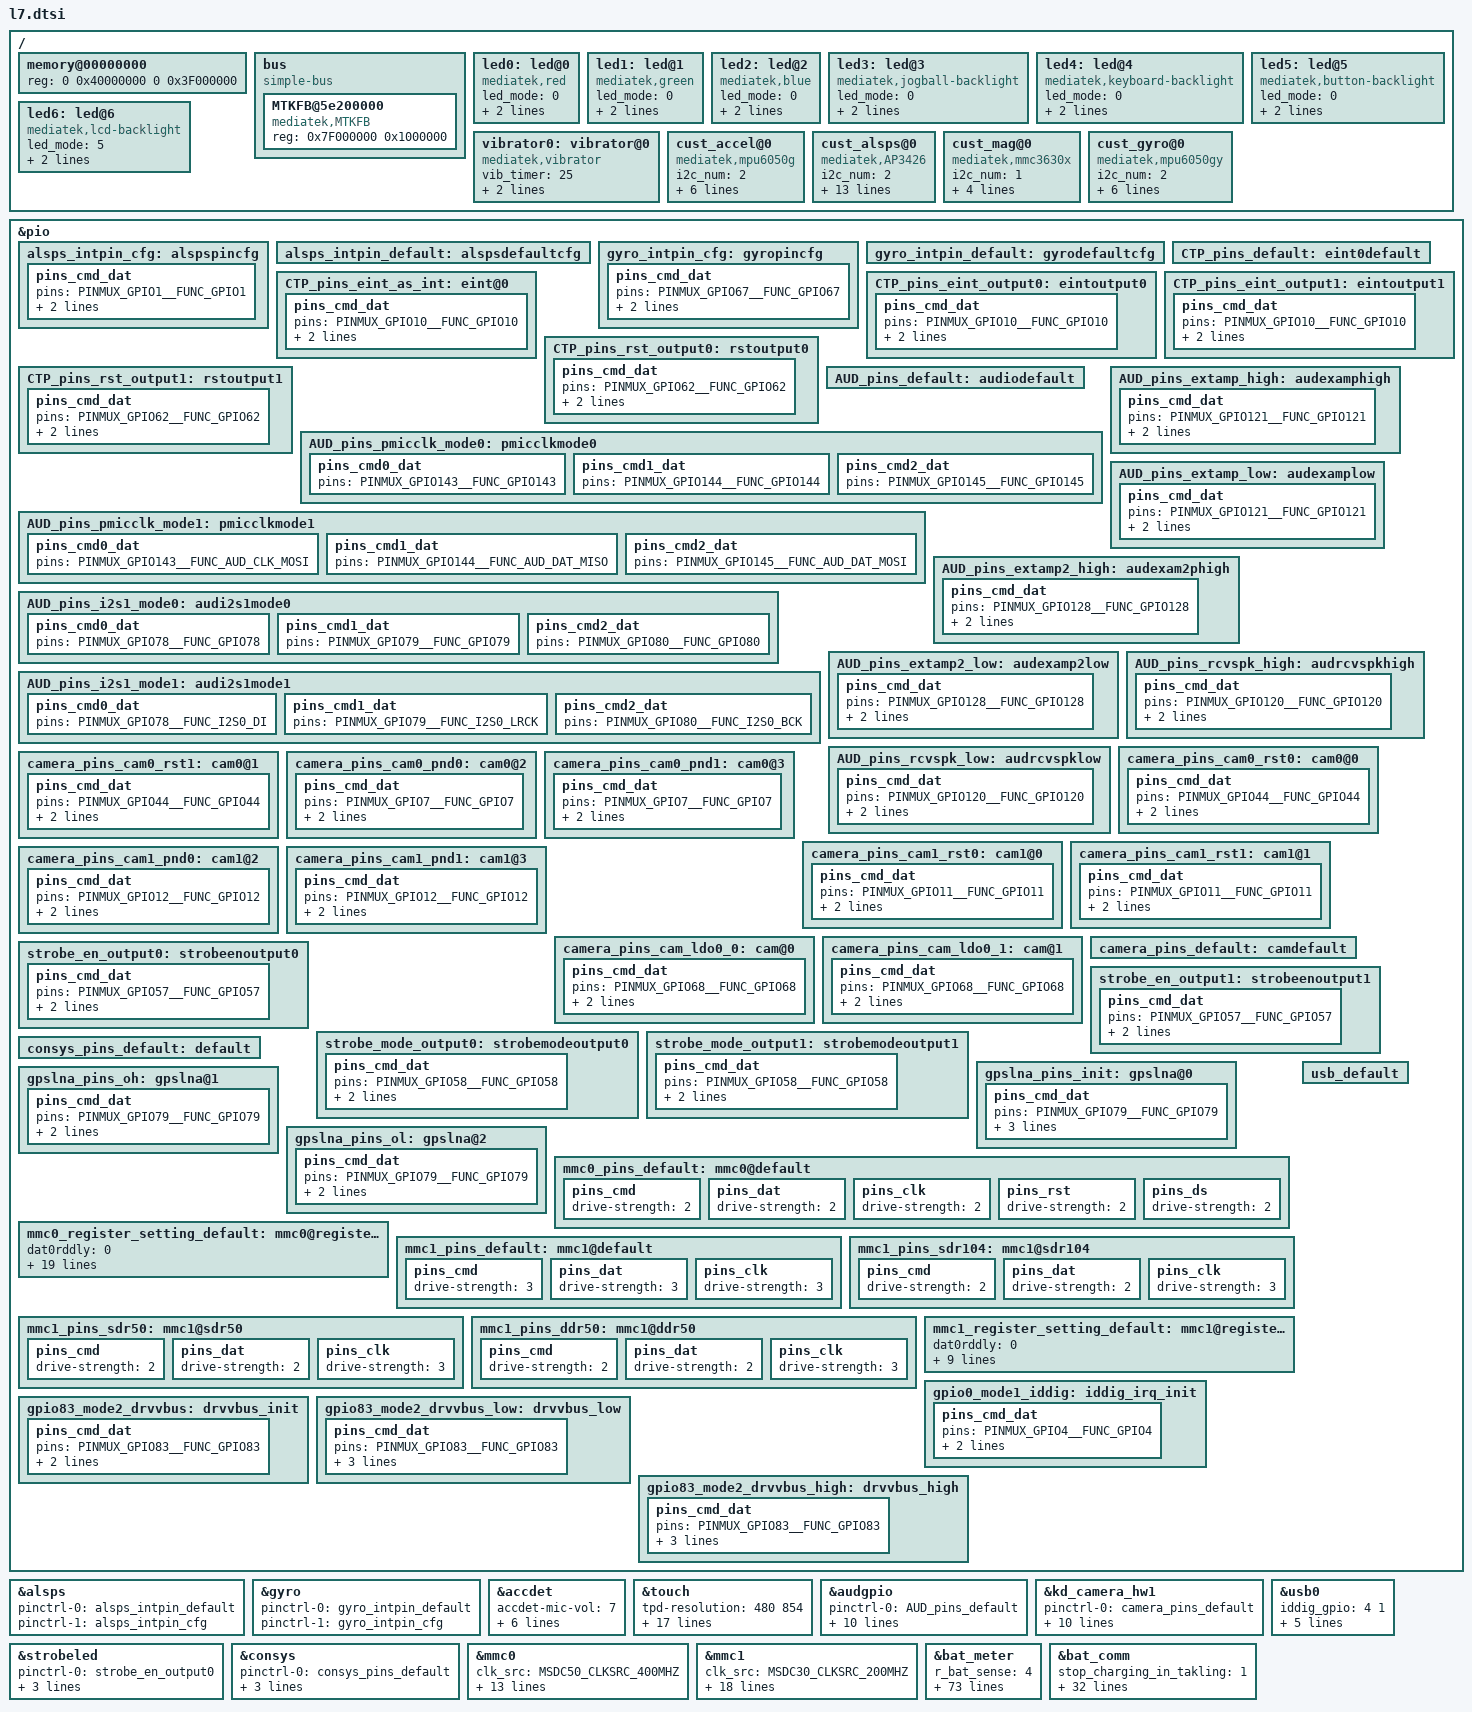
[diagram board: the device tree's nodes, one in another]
#include "mt6735m.dtsi"

/ {
memory@00000000 {
		device_type = "memory";
		reg = <0 0x40000000 0 0x3F000000>;
	};

	bus {
		compatible = "simple-bus";
		#address-cells = <1>;
		#size-cells = <1>;
		ranges = <0 0 0 0xffffffff>;

		MTKFB@5e200000 {
			compatible = "mediatek,MTKFB";
			reg = <0x7F000000 0x1000000>;
		};

	};
	led0:led@0 {
		compatible = "mediatek,red";
		led_mode = <0>;
		data = <1>;
		pwm_config = <0 0 0 0 0>;
	};
	led1:led@1 {
		compatible = "mediatek,green";
		led_mode = <0>;
		data = <1>;
		pwm_config = <0 0 0 0 0>;
	};
	led2:led@2 {
		compatible = "mediatek,blue";
		led_mode = <0>;
		data = <1>;
		pwm_config = <0 0 0 0 0>;
	};
	led3:led@3 {
		compatible = "mediatek,jogball-backlight";
		led_mode = <0>;
		data = <1>;
		pwm_config = <0 0 0 0 0>;
	};
	led4:led@4 {
		compatible = "mediatek,keyboard-backlight";
		led_mode = <0>;
		data = <1>;
		pwm_config = <0 0 0 0 0>;
	};
	led5:led@5 {
		compatible = "mediatek,button-backlight";
		led_mode = <0>;
		data = <1>;
		pwm_config = <0 0 0 0 0>;
	};
	led6:led@6 {
		compatible = "mediatek,lcd-backlight";
		led_mode = <5>;
		data = <1>;
		pwm_config = <0 0 0 0 0>;
	};
	vibrator0:vibrator@0 {
		compatible = "mediatek,vibrator";
		vib_timer = <25>;
		vib_limit = <9>;
		vib_vol= <5>;
	};
 /* sensor standardization */
		cust_accel@0 {
		compatible				= "mediatek,mpu6050g";
		i2c_num				= <2>;
		i2c_addr				= <0x68 0 0 0>;
		direction				= <7>;
		power_id				= <0xffff>;
		power_vol				= <0>;
		firlen					= <0>;
		is_batch_supported			= <0>;
		};

		cust_alsps@0 {
		compatible				= "mediatek,AP3426";
		i2c_num				= <2>;
		i2c_addr				= <0x1E 0 0 0>;
		polling_mode_ps			= <0>;
		polling_mode_als		= <1>;
		power_id				= <0xffff>;
		power_vol				= <0>;
		als_level = <0 1 1 7 15 15 100 1000 2000 3000 6000 10000 14000 18000 20000>;
		als_value = <40 40 90 90 160 160 225 320 640 1280 1280 2600 2600 2600 10240 10240>;
		ps_threshold_high		=  <300>;
		ps_threshold_low		=  <100>;
		is_batch_supported_ps	= <0>;
		is_batch_supported_als	= <0>;
		};

		cust_mag@0 {
		compatible			= "mediatek,mmc3630x";
		i2c_num				= <1>;
		i2c_addr			= <0x30 0 0 0>;
		direction			= <7>;
		power_id			= <0xffff>;
		power_vol			= <0>;
		/* is_batch_supported		= <0>; */
		};

		cust_gyro@0 {
		compatible				= "mediatek,mpu6050gy";
		i2c_num				= <2>;
		i2c_addr				= <0x69 0 0 0>;
		direction				= <7>;
		power_id				= <0xffff>;
		power_vol				= <0>;
		firlen					= <0>;
		is_batch_supported	= <0>;
		};
};
/* sensor gpio standization */
&pio {
	alsps_intpin_cfg: alspspincfg {

	    pins_cmd_dat {
			pins = <PINMUX_GPIO1__FUNC_GPIO1>;
			slew-rate = <0>;
			bias-pull-up = <00>;
		};
	};

	alsps_intpin_default: alspsdefaultcfg {

	};

	gyro_intpin_cfg: gyropincfg {

	    pins_cmd_dat {
			pins = <PINMUX_GPIO67__FUNC_GPIO67>;
			slew-rate = <0>;
			bias-pull-down = <00>;
		};
	};

	gyro_intpin_default: gyrodefaultcfg {

	};
};
&alsps {
	pinctrl-names = "pin_default", "pin_cfg";
	pinctrl-0 = <&alsps_intpin_default>;
	pinctrl-1 = <&alsps_intpin_cfg>;
	status = "okay";

};

&gyro {
	pinctrl-names = "pin_default", "pin_cfg";
	pinctrl-0 = <&gyro_intpin_default>;
	pinctrl-1 = <&gyro_intpin_cfg>;
	status = "okay";

};
/* sensor end */

&accdet {
		accdet-mic-vol = <7>;
		headset-mode-setting = <0x500 0x200 1 0x1F0 0x800 0x800 0x20>;
		accdet-plugout-debounce = <20>;
		/*1:ACC mode, 2:low cost without in bias, 6:low cost with in bias*/
		accdet-mic-mode = <2>;
		/*0--MD_MAX--UP_MAX--DW_MAX*/
		headset-three-key-threshold = <0 60 180 500>;
		/*0--MD_MAX--VOICE_MAX--UP_MAX--DW_MAX*/
		headset-four-key-threshold = <0 58 121 192 450>;
};
&touch {
	tpd-resolution = <480 854>;
	use-tpd-button = <0>;
	tpd-key-num = <3>;
	tpd-key-local= <139 172 158 0>;
	tpd-key-dim-local = <90 883 100 40 230 883 100 40 370 883 100 40 0 0 0 0>;
	tpd-max-touch-num = <5>;
	tpd-filter-enable = <1>;
	tpd-filter-pixel-density = <93>;
	tpd-filter-custom-prameters = <0 0 0 0 0 0 0 0 0 0 0 0>;
	tpd-filter-custom-speed = <0 0 0>;
	pinctrl-names = "default", "state_eint_as_int", "state_eint_output0", "state_eint_output1",
		"state_rst_output0", "state_rst_output1";
	pinctrl-0 = <&CTP_pins_default>;
	pinctrl-1 = <&CTP_pins_eint_as_int>;
	pinctrl-2 = <&CTP_pins_eint_output0>;
	pinctrl-3 = <&CTP_pins_eint_output1>;
	pinctrl-4 = <&CTP_pins_rst_output0>;
	pinctrl-5 = <&CTP_pins_rst_output1>;
	status = "okay";
};
&pio {
	CTP_pins_default: eint0default {
	};
	CTP_pins_eint_as_int: eint@0 {
		pins_cmd_dat {
			pins = <PINMUX_GPIO10__FUNC_GPIO10>;
			slew-rate = <0>;
			bias-disable;
		};
	};
	CTP_pins_eint_output0: eintoutput0 {
		pins_cmd_dat {
			pins = <PINMUX_GPIO10__FUNC_GPIO10>;
			slew-rate = <1>;
			output-low;
		};
	};
	CTP_pins_eint_output1: eintoutput1 {
		pins_cmd_dat {
			pins = <PINMUX_GPIO10__FUNC_GPIO10>;
			slew-rate = <1>;
			output-high;
		};
	};
	CTP_pins_rst_output0: rstoutput0 {
		pins_cmd_dat {
			pins = <PINMUX_GPIO62__FUNC_GPIO62>;
			slew-rate = <1>;
			output-low;
		};
	};
	CTP_pins_rst_output1: rstoutput1 {
		pins_cmd_dat {
			pins = <PINMUX_GPIO62__FUNC_GPIO62>;
			slew-rate = <1>;
			output-high;
		};
	};
};
/* TOUCH end */
/* AUDIO GPIO standardization */
&audgpio {
	pinctrl-names = "default", "audpmicclk-mode0", "audpmicclk-mode1", "audi2s1-mode0", "audi2s1-mode1", "extamp-pullhigh", "extamp-pulllow", "extamp2-pullhigh", "extamp2-pulllow", "rcvspk-pullhigh", "rcvspk-pulllow";
	pinctrl-0 = <&AUD_pins_default>;
	pinctrl-1 = <&AUD_pins_pmicclk_mode0>;
	pinctrl-2 = <&AUD_pins_pmicclk_mode1>;
	pinctrl-3 = <&AUD_pins_i2s1_mode0>;
	pinctrl-4 = <&AUD_pins_i2s1_mode1>;
	pinctrl-5 = <&AUD_pins_extamp_high>;
	pinctrl-6 = <&AUD_pins_extamp_low>;
	pinctrl-7 = <&AUD_pins_extamp2_high>;
	pinctrl-8 = <&AUD_pins_extamp2_low>;
	pinctrl-9 = <&AUD_pins_rcvspk_high>;
	pinctrl-10 = <&AUD_pins_rcvspk_low>;
	status = "okay";
};
&pio {
	AUD_pins_default: audiodefault {
	};
	AUD_pins_pmicclk_mode0: pmicclkmode0 {
		pins_cmd0_dat {
			pins = <PINMUX_GPIO143__FUNC_GPIO143>;
		};
		pins_cmd1_dat {
			pins = <PINMUX_GPIO144__FUNC_GPIO144>;
		};
		pins_cmd2_dat {
			pins = <PINMUX_GPIO145__FUNC_GPIO145>;
		};
	};
	AUD_pins_pmicclk_mode1: pmicclkmode1 {
		pins_cmd0_dat {
			pins = <PINMUX_GPIO143__FUNC_AUD_CLK_MOSI>;
		};
		pins_cmd1_dat {
			pins = <PINMUX_GPIO144__FUNC_AUD_DAT_MISO>;
		};
		pins_cmd2_dat {
			pins = <PINMUX_GPIO145__FUNC_AUD_DAT_MOSI>;
		};
	};
	AUD_pins_i2s1_mode0: audi2s1mode0 {
		pins_cmd0_dat {
			pins = <PINMUX_GPIO78__FUNC_GPIO78>;
		};
		pins_cmd1_dat {
			pins = <PINMUX_GPIO79__FUNC_GPIO79>;
		};
		pins_cmd2_dat {
			pins = <PINMUX_GPIO80__FUNC_GPIO80>;
		};
	};
	AUD_pins_i2s1_mode1: audi2s1mode1 {
		pins_cmd0_dat {
			pins = <PINMUX_GPIO78__FUNC_I2S0_DI>;
		};
		pins_cmd1_dat {
			pins = <PINMUX_GPIO79__FUNC_I2S0_LRCK>;
		};
		pins_cmd2_dat {
			pins = <PINMUX_GPIO80__FUNC_I2S0_BCK>;
		};
	};
	AUD_pins_extamp_high: audexamphigh {
		pins_cmd_dat {
			pins = <PINMUX_GPIO121__FUNC_GPIO121>;
				slew-rate = <1>;
				output-high;
		};
	};
	AUD_pins_extamp_low: audexamplow {
		pins_cmd_dat {
			pins = <PINMUX_GPIO121__FUNC_GPIO121>;
				slew-rate = <1>;
				output-low;
		};
	};
	AUD_pins_extamp2_high: audexam2phigh {
		pins_cmd_dat {
			pins = <PINMUX_GPIO128__FUNC_GPIO128>;
				slew-rate = <1>;
				output-high;
		};
	};
	AUD_pins_extamp2_low: audexamp2low {
		pins_cmd_dat {
			pins = <PINMUX_GPIO128__FUNC_GPIO128>;
				slew-rate = <1>;
				output-low;
		};
	};
	AUD_pins_rcvspk_high: audrcvspkhigh {
		pins_cmd_dat {
			pins = <PINMUX_GPIO120__FUNC_GPIO120>;
				slew-rate = <1>;
				output-high;
		};
	};
	AUD_pins_rcvspk_low: audrcvspklow {
		pins_cmd_dat {
			pins = <PINMUX_GPIO120__FUNC_GPIO120>;
				slew-rate = <1>;
				output-low;
		};
	};
};
/* AUDIO end */
/* CAMERA GPIO standardization */
&pio {
	camera_pins_cam0_rst0: cam0@0 {
	    pins_cmd_dat {
			pins = <PINMUX_GPIO44__FUNC_GPIO44>;/*GPIO_CAMERA_CMRST_PIN*/
			slew-rate = <1>; /*direction 0:in, 1:out*/
			output-low;/*direction out used only. output_low or high*/
		};
	};
	camera_pins_cam0_rst1: cam0@1 {
	    pins_cmd_dat {
			pins = <PINMUX_GPIO44__FUNC_GPIO44>;/*GPIO_CAMERA_CMRST_PIN*/
			slew-rate = <1>;
			output-high;
		};
	};
	camera_pins_cam0_pnd0: cam0@2 {
	    pins_cmd_dat {
			pins = <PINMUX_GPIO7__FUNC_GPIO7>;/*GPIO_CAMERA_CMPDN_PIN*/
			slew-rate = <1>;
			output-low;
		};
	};
	camera_pins_cam0_pnd1: cam0@3 {
	    pins_cmd_dat {
			pins = <PINMUX_GPIO7__FUNC_GPIO7>;/*GPIO_CAMERA_CMPDN_PIN*/
			slew-rate = <1>;
			output-high;
		};
	};
	camera_pins_cam1_rst0: cam1@0 {
	    pins_cmd_dat {
			pins = <PINMUX_GPIO11__FUNC_GPIO11>;/*GPIO_CAMERA_CMRST1_PIN*/
			slew-rate = <1>; /*direction 0:in, 1:out*/
			output-low;/*direction out used only. output_low or high*/
		};
	};
	camera_pins_cam1_rst1: cam1@1 {
	    pins_cmd_dat {
			pins = <PINMUX_GPIO11__FUNC_GPIO11>;/*GPIO_CAMERA_CMRST1_PIN*/
			slew-rate = <1>;
			output-high;
		};
	};
	camera_pins_cam1_pnd0: cam1@2 {
	    pins_cmd_dat {
			pins = <PINMUX_GPIO12__FUNC_GPIO12>;/*GPIO_CAMERA_CMPDN1_PIN*/
			slew-rate = <1>;
			output-low;
		};
	};
	camera_pins_cam1_pnd1: cam1@3 {
	    pins_cmd_dat {
			pins = <PINMUX_GPIO12__FUNC_GPIO12>;/*GPIO_CAMERA_CMPDN1_PIN*/
			slew-rate = <1>;
			output-high;
		};
	};
	camera_pins_cam_ldo0_0: cam@0 {
	    pins_cmd_dat {
			pins = <PINMUX_GPIO68__FUNC_GPIO68>;/*GPIO_SPI_MOSI_PIN*/
			slew-rate = <1>;
			output-low;
		};
	};
	camera_pins_cam_ldo0_1: cam@1 {
		pins_cmd_dat {
			pins = <PINMUX_GPIO68__FUNC_GPIO68>;/*GPIO_SPI_MOSI_PIN*/
			slew-rate = <1>;
			output-high;
		};
	};
	camera_pins_default: camdefault {
	};

};

&kd_camera_hw1 {
	pinctrl-names = "default", "cam0_rst0", "cam0_rst1", "cam0_pnd0", "cam0_pnd1",
			"cam1_rst0", "cam1_rst1", "cam1_pnd0", "cam1_pnd1","cam_ldo0_0", "cam_ldo0_1";
	pinctrl-0 = <&camera_pins_default>;
	pinctrl-1 = <&camera_pins_cam0_rst0>;
	pinctrl-2 = <&camera_pins_cam0_rst1>;
	pinctrl-3 = <&camera_pins_cam0_pnd0>;
	pinctrl-4 = <&camera_pins_cam0_pnd1>;
	pinctrl-5 = <&camera_pins_cam1_rst0>;
	pinctrl-6 = <&camera_pins_cam1_rst1>;
	pinctrl-7 = <&camera_pins_cam1_pnd0>;
	pinctrl-8 = <&camera_pins_cam1_pnd1>;
	pinctrl-9 = <&camera_pins_cam_ldo0_0>;
	pinctrl-10 = <&camera_pins_cam_ldo0_1>;
	status = "okay";

};
/* CAMERA GPIO end */

/* strobe standardization */
&strobeled {
	pinctrl-names = "state_strobe_en_output0", "state_strobe_en_output1", "state_strobe_mode_output0", "state_strobe_mode_output1";
	pinctrl-0 = <&strobe_en_output0>;
	pinctrl-1 = <&strobe_en_output1>;
	pinctrl-2 = <&strobe_mode_output0>;
	pinctrl-3 = <&strobe_mode_output1>;
	status = "okay";
};
&pio {
	strobe_en_output0: strobeenoutput0 {
		pins_cmd_dat {
			pins = <PINMUX_GPIO57__FUNC_GPIO57>;
			slew-rate = <1>;
			output-low;
		};
	};
	strobe_en_output1: strobeenoutput1 {
		pins_cmd_dat {
			pins = <PINMUX_GPIO57__FUNC_GPIO57>;
			slew-rate = <1>;
			output-high;
		};
	};
	strobe_mode_output0: strobemodeoutput0 {
		pins_cmd_dat {
			pins = <PINMUX_GPIO58__FUNC_GPIO58>;
			slew-rate = <1>;
			output-low;
		};
	};
	strobe_mode_output1: strobemodeoutput1 {
		pins_cmd_dat {
			pins = <PINMUX_GPIO58__FUNC_GPIO58>;
			slew-rate = <1>;
			output-high;
		};
	};
};
/* strobe end */

/* CONSYS GPIO standardization */
&pio {
	consys_pins_default: default {

	};

	gpslna_pins_init: gpslna@0 {

	    pins_cmd_dat {
			pins = <PINMUX_GPIO79__FUNC_GPIO79>;
			slew-rate = <0>;
			bias-disable;
			output-low;
		};
	};

	gpslna_pins_oh: gpslna@1 {

	    pins_cmd_dat {
			pins = <PINMUX_GPIO79__FUNC_GPIO79>;
			slew-rate = <1>;
			output-high;
		};
	};

	gpslna_pins_ol: gpslna@2 {

	    pins_cmd_dat {
			pins = <PINMUX_GPIO79__FUNC_GPIO79>;
			slew-rate = <1>;
			output-low;
		};
	};

};

&consys {
	pinctrl-names = "default", "gps_lna_state_init", "gps_lna_state_oh", "gps_lna_state_ol";
	pinctrl-0 = <&consys_pins_default>;
	pinctrl-1 = <&gpslna_pins_init>;
	pinctrl-2 = <&gpslna_pins_oh>;
	pinctrl-3 = <&gpslna_pins_ol>;
	status = "okay";

};
/* CONSYS end */

/* mmc start */
&mmc0 {
		clk_src = /bits/ 8 <MSDC50_CLKSRC_400MHZ>;
		bus-width = <8>;
		max-frequency = <200000000>;
		cap-mmc-highspeed;
		msdc-sys-suspend;
		mmc-ddr-1_8v;
		mmc-hs200-1_8v;
		mmc-hs400-1_8v;
		non-removable;
		pinctl = <&mmc0_pins_default>;
		register_setting = <&mmc0_register_setting_default>;
		host_function = /bits/ 8 <MSDC_EMMC>;
		bootable;
		status = "okay";
};

&mmc1 {
		clk_src = /bits/ 8 <MSDC30_CLKSRC_200MHZ>;
		bus-width = <4>;
		max-frequency = <200000000>;
		msdc-sys-suspend;
		cap-sd-highspeed;
		sd-uhs-sdr12;
		sd-uhs-sdr25;
		sd-uhs-sdr50;
		sd-uhs-sdr104;
		sd-uhs-ddr50;
		pinctl = <&mmc1_pins_default>;
		pinctl_sdr104 = <&mmc1_pins_sdr104>;
		pinctl_sdr50 = <&mmc1_pins_sdr50>;
		pinctl_ddr50 = <&mmc1_pins_ddr50>;
		register_setting = <&mmc1_register_setting_default>;
		host_function = /bits/ 8 <MSDC_SD>;
		cd_level = /bits/ 8 <MSDC_CD_LOW>;
		cd-gpios = <&pio 5 0>;
		status = "okay";
};

&pio {
	mmc0_pins_default: mmc0@default {
			pins_cmd {
				drive-strength = /bits/ 8 <2>;
			};
			pins_dat {
				drive-strength = /bits/ 8 <2>;
			};
			pins_clk {
				drive-strength = /bits/ 8 <2>;
			};
			pins_rst {
				drive-strength = /bits/ 8 <2>;
			};
			pins_ds {
				drive-strength = /bits/ 8 <2>;
			};
	};

	mmc0_register_setting_default: mmc0@register_default {
		dat0rddly      = /bits/ 8 <0>;
		dat1rddly      = /bits/ 8 <0>;
		dat2rddly      = /bits/ 8 <0>;
		dat3rddly      = /bits/ 8 <0>;
		dat4rddly      = /bits/ 8 <0>;
		dat5rddly      = /bits/ 8 <0>;
		dat6rddly      = /bits/ 8 <0>;
		dat7rddly      = /bits/ 8 <0>;
		datwrddly      = /bits/ 8 <0>;
		cmdrrddly      = /bits/ 8 <0>;
		cmdrddly       = /bits/ 8 <0>;
		cmd_edge = /bits/ 8 <MSDC_SMPL_FALLING>;
		rdata_edge = /bits/ 8 <MSDC_SMPL_FALLING>;
		wdata_edge = /bits/ 8 <MSDC_SMPL_FALLING>;

		ett-hs200-cells = <12>;
		ett-hs200-default = <OFFSET_MSDC_PATCH_BIT0	MSDC_PB0_INT_DAT_LATCH_CK_SEL 0x0
			OFFSET_MSDC_PATCH_BIT0	MSDC_PB0_CKGEN_MSDC_DLY_SEL   0x0
			OFFSET_MSDC_PATCH_BIT1	MSDC_PB1_CMD_RSP_TA_CNTR      0x1
			OFFSET_MSDC_IOCON		MSDC_IOCON_RSPL               0x1
			OFFSET_MSDC_PAD_TUNE0	MSDC_PAD_TUNE0_CMDRDLY        0x0
			OFFSET_MSDC_PAD_TUNE0	MSDC_PAD_TUNE0_CMDRRDLY       0x6
			OFFSET_MSDC_PATCH_BIT1		MSDC_PB1_WRDAT_CRCS_TA_CNTR   0x1
			OFFSET_MSDC_PAD_TUNE0	MSDC_PAD_TUNE0_DATWRDLY       0xf
			OFFSET_MSDC_IOCON			MSDC_IOCON_W_D0SPL            0x1
			OFFSET_MSDC_DAT_RDDLY0		MSDC_DAT_RDDLY0_D0            0x5
			OFFSET_MSDC_PAD_TUNE0	MSDC_PAD_TUNE0_DATRRDLY       0x12
			OFFSET_MSDC_IOCON		MSDC_IOCON_R_D_SMPL           0x0>;

		ett-hs400-cells = <8>;
		ett-hs400-default = <OFFSET_MSDC_PATCH_BIT0	MSDC_PB0_INT_DAT_LATCH_CK_SEL	0x0
			OFFSET_MSDC_PATCH_BIT0		MSDC_PB0_CKGEN_MSDC_DLY_SEL		0x0
			OFFSET_EMMC50_PAD_DS_TUNE	MSDC_EMMC50_PAD_DS_TUNE_DLY1	0x2
			OFFSET_EMMC50_PAD_DS_TUNE	MSDC_EMMC50_PAD_DS_TUNE_DLY3	0x12
			OFFSET_MSDC_PATCH_BIT1			MSDC_PB1_CMD_RSP_TA_CNTR	0x1
			OFFSET_MSDC_IOCON		MSDC_IOCON_RSPL				0x1
			OFFSET_MSDC_PAD_TUNE0			MSDC_PAD_TUNE0_CMDRDLY		0x0
			OFFSET_MSDC_PAD_TUNE0		MSDC_PAD_TUNE0_CMDRRDLY		0xb>;
	};

	mmc1_pins_default: mmc1@default {
			pins_cmd {
				drive-strength = /bits/ 8 <3>;
			};
			pins_dat {
				drive-strength = /bits/ 8 <3>;
			};
			pins_clk {
				drive-strength = /bits/ 8 <3>;
			};
	};

	mmc1_pins_sdr104: mmc1@sdr104 {
			pins_cmd {
				drive-strength = /bits/ 8 <2>;
			};
			pins_dat {
				drive-strength = /bits/ 8 <2>;
			};
			pins_clk {
				drive-strength = /bits/ 8 <3>;
			};
	};

	mmc1_pins_sdr50: mmc1@sdr50 {
			pins_cmd {
				drive-strength = /bits/ 8 <2>;
			};
			pins_dat {
				drive-strength = /bits/ 8 <2>;
			};
			pins_clk {
				drive-strength = /bits/ 8 <3>;
			};
	};

	mmc1_pins_ddr50: mmc1@ddr50 {
			pins_cmd {
				drive-strength = /bits/ 8 <2>;
			};
			pins_dat {
				drive-strength = /bits/ 8 <2>;
			};
			pins_clk {
				drive-strength = /bits/ 8 <3>;
			};
	};

	mmc1_register_setting_default: mmc1@register_default {
				dat0rddly      = /bits/ 8 <0>;
				dat1rddly      = /bits/ 8 <0>;
				dat2rddly      = /bits/ 8 <0>;
				dat3rddly      = /bits/ 8 <0>;
				datwrddly      = /bits/ 8 <0>;
				cmdrrddly      = /bits/ 8 <0>;
				cmdrddly       = /bits/ 8 <0>;
				cmd_edge = /bits/ 8 <MSDC_SMPL_FALLING>;
				rdata_edge = /bits/ 8 <MSDC_SMPL_FALLING>;
				wdata_edge = /bits/ 8 <MSDC_SMPL_FALLING>;
	};
};
/* mmc end */

/* NFC GPIO standardization */
/*
&pio {
	nfc_default: mtknfc {

	};

	nfc_ven_high: state_ven_high {
		pins_cmd_dat {
			pins = <PINMUX_GPIO4__FUNC_GPIO4>;
			slew-rate = <1>;
			output-high;
		};
	};

	nfc_ven_low: state_ven_low {
		pins_cmd_dat {
			pins = <PINMUX_GPIO4__FUNC_GPIO4>;
			slew-rate = <1>;
			output-low;
		};
	};

	nfc_rst_high: state_rst_high {
		pins_cmd_dat {
			pins = <PINMUX_GPIO3__FUNC_GPIO3>;
			slew-rate = <1>;
			output-high;
		};
	};

	nfc_rst_low: state_rst_low {
		pins_cmd_dat {
			pins = <PINMUX_GPIO3__FUNC_GPIO3>;
			slew-rate = <1>;
			output-low;
		};
	};

	nfc_eint_high: state_eint_high {
		pins_cmd_dat {
			pins = <PINMUX_GPIO1__FUNC_GPIO1>;
			slew-rate = <1>;
			output-high;
		};
	};

	nfc_eint_low: state_eint_low {
		pins_cmd_dat {
			pins = <PINMUX_GPIO1__FUNC_GPIO1>;
			slew-rate = <1>;
			output-low;
		};
	};

	nfc_irq_init: state_irq_init {
		pins_cmd_dat {
			pins = <PINMUX_GPIO2__FUNC_GPIO2>;
			slew-rate = <0>;
			bias-pull-down = <00>;
		};
	};
};

&nfc {
	pinctrl-names = "mtknfc", "ven_high", "ven_low", "rst_high", "rst_low", "eint_high", "eint_low", "irq_init";
	pinctrl-0 = <&nfc_default>;
	pinctrl-1 = <&nfc_ven_high>;
	pinctrl-2 = <&nfc_ven_low>;
	pinctrl-3 = <&nfc_rst_high>;
	pinctrl-4 = <&nfc_rst_low>;
	pinctrl-5 = <&nfc_eint_high>;
	pinctrl-6 = <&nfc_eint_low>;
	pinctrl-7 = <&nfc_irq_init>;
	status = "disable";
};
*/
/* NFC end */

/* USB GPIO Kernal Standardization start */
&pio {
	usb_default: usb_default {
	};

	gpio0_mode1_iddig: iddig_irq_init {
		pins_cmd_dat {
			pins = <PINMUX_GPIO4__FUNC_GPIO4>;
			slew-rate = <0>;
			bias-pull-up = <00>;
		};
	};

	gpio83_mode2_drvvbus: drvvbus_init {
		pins_cmd_dat {
			pins = <PINMUX_GPIO83__FUNC_GPIO83>;
			slew-rate = <1>;
			bias-pull-down = <00>;
		};
	};

	gpio83_mode2_drvvbus_low: drvvbus_low {
		pins_cmd_dat {
			pins = <PINMUX_GPIO83__FUNC_GPIO83>;
			slew-rate = <1>;
			output-low;
			bias-pull-down = <00>;
		};
	};

	gpio83_mode2_drvvbus_high: drvvbus_high {
		pins_cmd_dat {
			pins = <PINMUX_GPIO83__FUNC_GPIO83>;
			slew-rate = <1>;
			output-high;
			bias-pull-down = <00>;
		};
	};
};

&usb0 {
	iddig_gpio = <4 1>;
	pinctrl-names = "usb_default", "iddig_irq_init", "drvvbus_init", "drvvbus_low", "drvvbus_high";
	pinctrl-0 = <&usb_default>;
	pinctrl-1 = <&gpio0_mode1_iddig>;
	pinctrl-2 = <&gpio83_mode2_drvvbus>;
	pinctrl-3 = <&gpio83_mode2_drvvbus_low>;
	pinctrl-4 = <&gpio83_mode2_drvvbus_high>;
	status = "okay";
};
/* USB GPIO Kernal Standardization end */


/*for battery*/
&bat_meter{
	/* cust_battery_meter.h */
	/* ADC resistor  */
	r_bat_sense = <4 >;
	r_i_sense = <4 >;
	r_charger_1 = <330 >;
	r_charger_2 = <39 >;
	temperature_t0 = <110 >;
	temperature_t1 = <0 >;
	temperature_t2 = <25 >;
	temperature_t3 = <50 >;
	temperature_t = <255 >;	/* this should be fixed, never change the value */
	fg_meter_resistance = <0 >;

	/* Qmax for 0mA */
	q_max_pos_50 = <2035 >;
	q_max_pos_25 = <2074 >;
	q_max_pos_0 = <1959 >;
	q_max_neg_10 = <1854 >;
	/* Qmax for 400mA, said high current */
	q_max_pos_50_h_current = <2020 >;
	q_max_pos_25_h_current = <2055 >;
	q_max_pos_0_h_current = <1832 >;
	q_max_neg_10_h_current = <1716 >;
	/* Discharge percentage, 1: D5, 0: D2 */
	oam_d5 = <1 >;

	change_tracking_point = <1 >;
	/* SW OCV tracking setting */
	cust_tracking_point = <1 >;
	cust_r_sense = <56 >;
	cust_hw_cc = <0 >;
	aging_tuning_value = <103 >;
	cust_r_fg_offset = <0 >;
	ocv_board_compesate = <0 >;
	r_fg_board_base = <1000 >;
	r_fg_board_slope = <1000 >;
	car_tune_value = <86 >;

	/* HW Fuel gague  */
	current_detect_r_fg = <10 >;	/* Unit: mA */
	minerroroffset = <1000 >;
	fg_vbat_average_size = <18 >;
	r_fg_value = <10 >;	/* Unit: mOhm */

	cust_poweron_delta_capacity_tolrance = <30 >;
	cust_poweron_low_capacity_tolrance = <5 >;
	cust_poweron_max_vbat_tolrance = <90 >;
	cust_poweron_delta_vbat_tolrance = <30 >;
	cust_poweron_delta_hw_sw_ocv_capacity_tolrance = <10 >;

	/* Fixed battery temperature */
	fixed_tbat_25 = <0 >;
	/* Dynamic change wake up period of battery thread when suspend */
	vbat_normal_wakeup = <3600 >;	/* Unit: mV */
	vbat_low_power_wakeup = <3500 >;	/* Unit: mV */
	normal_wakeup_period = <5400 >;	/* Unit: second */
	low_power_wakeup_period = <300 >;	/* Unit: second */
	close_poweroff_wakeup_period = <30 >;	/* Unit: second */

	rbat_pull_up_r = <16900 >;
	rbat_pull_up_volt = <1800 >;


	batt_temperature_table_num = <17 >;
	batt_temperature_table = <
	(-20) 68237
	(-15) 53650
	(-10) 42506
	(-5) 33892
	0 27219
	5 22021
	10 17926
	15 14674
	20 12081
	25 10000
	30 8315 
	35 6948 
	40 5834 
	45 4917 
	50 4161 
	55 3535 
	60 3014 >;

	battery_profile_t0_num = <100 >;
	battery_profile_t0 = <0 	4339 
1 	4320 
2 	4305 
3 	4292 
4 	4279 
5 	4268 
6 	4256 
7 	4244 
8 	4233 
9 	4222 
10 	4211 
11 	4200 
12 	4189 
13 	4178 
14 	4168 
15 	4157 
16 	4147 
17 	4136 
18 	4125 
19 	4115 
20 	4104 
21 	4094 
22 	4084 
23 	4073 
24 	4066 
25 	4059 
26 	4052 
27 	4040 
28 	4025 
29 	4008 
29 	3994 
30 	3983 
31 	3974 
32 	3967 
33 	3961 
34 	3955 
35 	3948 
36 	3941 
37 	3932 
38 	3924 
39 	3915 
40 	3906 
41 	3898 
42 	3890 
43 	3882 
44 	3874 
45 	3867 
46 	3861 
47 	3855 
48 	3849 
49 	3844 
50 	3838 
51 	3833 
52 	3829 
53 	3824 
54 	3820 
55 	3815 
56 	3811 
57 	3807 
58 	3804 
59 	3800 
60 	3797 
61 	3793 
62 	3790 
63 	3787 
64 	3784 
65 	3781 
66 	3778 
67 	3775 
68 	3773 
69 	3770 
70 	3768 
71 	3766 
72 	3764 
73 	3762 
74 	3759 
75 	3757 
76 	3754 
77 	3751 
78 	3748 
79 	3745 
80 	3742 
81 	3738 
82 	3734 
83 	3730 
84 	3725 
85 	3719 
86 	3714 
86 	3708 
87 	3701 
88 	3694 
89 	3689 
90 	3686 
91 	3684 
92 	3681 
93 	3678 
94 	3673 
95 	3664 
96 	3643 
97 	3606 
98 	3552 
99 	3479 
100 	3372 

	 >;

	battery_profile_t1_num = <100 >;
	battery_profile_t1 = <0 	4322 
1 	4305 
2 	4291 
3 	4278 
4 	4266 
5 	4255 
6 	4244 
7 	4232 
8 	4221 
9 	4210 
10 	4199 
11 	4188 
12 	4177 
13 	4167 
14 	4156 
15 	4145 
16 	4134 
17 	4124 
18 	4113 
19 	4102 
20 	4092 
21 	4081 
22 	4071 
23 	4061 
24 	4053 
25 	4046 
26 	4038 
27 	4026 
28 	4010 
29 	3993 
30 	3979 
31 	3968 
32 	3959 
33 	3952 
34 	3946 
35 	3940 
36 	3933 
37 	3925 
38 	3916 
39 	3907 
40 	3899 
41 	3891 
42 	3883 
43 	3876 
44 	3868 
45 	3862 
46 	3855 
47 	3849 
48 	3843 
49 	3838 
50 	3832 
51 	3827 
52 	3823 
53 	3818 
54 	3813 
54 	3809 
55 	3805 
56 	3801 
57 	3796 
58 	3793 
59 	3789 
60 	3786 
61 	3782 
62 	3779 
63 	3775 
64 	3772 
65 	3770 
66 	3766 
67 	3764 
68 	3761 
69 	3758 
70 	3756 
71 	3753 
72 	3751 
73 	3748 
74 	3746 
75 	3743 
76 	3740 
77 	3737 
78 	3734 
79 	3731 
80 	3728 
81 	3724 
82 	3720 
83 	3715 
84 	3710 
85 	3704 
86 	3699 
87 	3693 
88 	3686 
89 	3680 
90 	3677 
91 	3675 
92 	3673 
93 	3670 
94 	3666 
95 	3658 
96 	3640 
97 	3607 
98 	3557 
99 	3489 
100 	3392 
100 	3219 

	>;

	battery_profile_t2_num = <100 >;
	battery_profile_t2 = <0 	4336 
1 	4301 
2 	4280 
3 	4263 
4 	4247 
5 	4232 
6 	4218 
7 	4204 
8 	4191 
9 	4179 
10 	4167 
11 	4154 
12 	4143 
13 	4131 
14 	4120 
15 	4108 
16 	4096 
17 	4086 
18 	4076 
19 	4067 
20 	4057 
21 	4047 
22 	4036 
23 	4023 
24 	4008 
25 	3993 
26 	3979 
27 	3966 
28 	3955 
29 	3944 
30 	3935 
30 	3927 
31 	3920 
32 	3914 
33 	3907 
34 	3900 
35 	3894 
36 	3887 
37 	3881 
38 	3875 
39 	3868 
40 	3862 
41 	3856 
42 	3850 
43 	3844 
44 	3838 
45 	3833 
46 	3828 
47 	3823 
48 	3818 
49 	3813 
50 	3808 
51 	3803 
52 	3799 
53 	3795 
54 	3791 
55 	3787 
56 	3784 
57 	3781 
58 	3778 
59 	3775 
60 	3773 
61 	3770 
62 	3768 
63 	3766 
64 	3764 
65 	3761 
66 	3759 
67 	3757 
68 	3755 
69 	3753 
70 	3751 
71 	3748 
72 	3746 
73 	3743 
74 	3741 
75 	3738 
76 	3736 
77 	3733 
78 	3730 
79 	3726 
80 	3723 
81 	3719 
82 	3715 
83 	3711 
84 	3707 
85 	3703 
86 	3699 
87 	3694 
88 	3690 
89 	3685 
90 	3679 
90 	3672 
91 	3665 
92 	3656 
93 	3644 
94 	3629 
95 	3608 
96 	3581 
97 	3545 
98 	3497 
99 	3432 
100 	3396 

	>;

	battery_profile_t3_num = <100 >;
	battery_profile_t3 = <0 	4341 
1 	4292 
2 	4264 
3 	4240 
4 	4219 
5 	4200 
6 	4182 
7 	4164 
8 	4148 
9 	4133 
10 	4119 
11 	4107 
12 	4094 
13 	4082 
14 	4068 
15 	4054 
16 	4038 
17 	4023 
18 	4008 
18 	3994 
19 	3981 
20 	3970 
21 	3960 
22 	3950 
23 	3942 
24 	3933 
25 	3925 
26 	3917 
27 	3910 
28 	3902 
29 	3894 
30 	3887 
31 	3879 
32 	3873 
33 	3866 
34 	3859 
35 	3853 
36 	3846 
37 	3840 
38 	3835 
39 	3829 
40 	3824 
41 	3819 
42 	3815 
43 	3811 
44 	3807 
45 	3803 
46 	3800 
47 	3796 
48 	3793 
49 	3790 
50 	3787 
51 	3784 
52 	3781 
53 	3779 
53 	3776 
54 	3774 
55 	3771 
56 	3769 
57 	3766 
58 	3764 
59 	3761 
60 	3759 
61 	3757 
62 	3754 
63 	3752 
64 	3750 
65 	3748 
66 	3745 
67 	3742 
68 	3739 
69 	3737 
70 	3734 
71 	3732 
72 	3729 
73 	3726 
74 	3723 
75 	3720 
76 	3717 
77 	3713 
78 	3710 
79 	3706 
80 	3702 
81 	3698 
82 	3694 
83 	3689 
84 	3684 
85 	3679 
86 	3673 
87 	3667 
88 	3660 
89 	3653 
89 	3643 
90 	3633 
91 	3622 
92 	3572 
93 	3562 
94 	3546 
96 	3526 
97 	3482 
98 	3460 
99 	3444 
100 	3390 

	>;

	r_profile_t0_num = <100 >;
	r_profile_t0 = <0 	245 
1 	245 
2 	245 
3 	247 
4 	246 
5 	247 
6 	247 
7 	247 
8 	247 
9 	247 
10 	247 
11 	248 
12 	248 
13 	248 
14 	248 
15 	248 
16 	250 
17 	250 
18 	250 
19 	250 
20 	251 
21 	252 
22 	253 
23 	252 
24 	254 
25 	257 
26 	258 
27 	258 
28 	255 
29 	254 
29 	253 
30 	254 
31 	253 
32 	256 
33 	257 
34 	257 
35 	255 
36 	253 
37 	251 
38 	249 
39 	246 
40 	245 
41 	243 
42 	240 
43 	240 
44 	237 
45 	237 
46 	237 
47 	236 
48 	236 
49 	236 
50 	236 
51 	235 
52 	235 
53 	236 
54 	236 
55 	236 
56 	236 
57 	236 
58 	238 
59 	238 
60 	238 
61 	239 
62 	238 
63 	239 
64 	238 
65 	240 
66 	240 
67 	240 
68 	240 
69 	240 
70 	240 
71 	240 
72 	242 
73 	243 
74 	243 
75 	244 
76 	244 
77 	243 
78 	244 
79 	245 
80 	246 
81 	247 
82 	248 
83 	248 
84 	250 
85 	251 
86 	252 
86 	254 
87 	256 
88 	256 
89 	258 
90 	261 
91 	264 
92 	269 
93 	276 
94 	285 
95 	293 
96 	301 
97 	308 
98 	319 
99 	344 
100 	385 

	>;

	r_profile_t1_num = <100 >;
	r_profile_t1 = <0 	253 
1 	253 
2 	253 
3 	254 
4 	253 
5 	253 
6 	254 
7 	252 
8 	252 
9 	253 
10 	251 
11 	251 
12 	251 
13 	252 
14 	251 
15 	251 
16 	252 
17 	251 
18 	253 
19 	252 
20 	254 
21 	254 
22 	253 
23 	254 
24 	255 
25 	257 
26 	258 
27 	257 
28 	254 
29 	253 
30 	252 
31 	252 
32 	251 
33 	252 
34 	253 
35 	251 
36 	251 
37 	247 
38 	243 
39 	242 
40 	240 
41 	239 
42 	237 
43 	236 
44 	235 
45 	234 
46 	234 
47 	233 
48 	233 
49 	232 
50 	232 
51 	232 
52 	232 
53 	233 
54 	233 
54 	232 
55 	233 
56 	233 
57 	233 
58 	234 
59 	233 
60 	234 
61 	234 
62 	234 
63 	234 
64 	233 
65 	235 
66 	235 
67 	236 
68 	235 
69 	235 
70 	236 
71 	236 
72 	235 
73 	236 
74 	236 
75 	236 
76 	236 
77 	236 
78 	237 
79 	238 
80 	239 
81 	238 
82 	239 
83 	240 
84 	240 
85 	241 
86 	242 
87 	243 
88 	244 
89 	244 
90 	245 
91 	249 
92 	252 
93 	256 
94 	262 
95 	269 
96 	273 
97 	276 
98 	283 
99 	297 
100 	320 
100 	392 

	>;

	r_profile_t2_num = <100 >;
	r_profile_t2 = <0 	748 
1 	748 
2 	750 
3 	746 
4 	739 
5 	732 
6 	726 
7 	718 
8 	712 
9 	706 
10 	699 
11 	692 
12 	687 
13 	681 
14 	674 
15 	667 
16 	661 
17 	657 
18 	656 
19 	653 
20 	652 
21 	649 
22 	646 
23 	640 
24 	628 
25 	619 
26 	610 
27 	602 
28 	599 
29 	595 
30 	593 
30 	592 
31 	592 
32 	592 
33 	591 
34 	591 
35 	590 
36 	588 
37 	588 
38 	587 
39 	586 
40 	584 
41 	585 
42 	585 
43 	582 
44 	583 
45 	584 
46 	583 
47 	583 
48 	586 
49 	585 
50 	585 
51 	586 
52 	588 
53 	588 
54 	590 
55 	589 
56 	592 
57 	595 
58 	597 
59 	601 
60 	602 
61 	605 
62 	610 
63 	613 
64 	616 
65 	622 
66 	624 
67 	629 
68 	636 
69 	640 
70 	645 
71 	650 
72 	655 
73 	661 
74 	670 
75 	676 
76 	686 
77 	695 
78 	703 
79 	716 
80 	725 
81 	736 
82 	751 
83 	764 
84 	781 
85 	798 
86 	817 
87 	842 
88 	864 
89 	892 
90 	928 
90 	963 
91 	1008 
92 	1062 
93 	1118 
94 	1193 
95 	1267 
96 	1345 
97 	1422 
98 	1482 
99 	1560 
100 	1585 

	>;

	r_profile_t3_num = <100 >;
	r_profile_t3 = <0 	879
1 	879
2 	922
3 	913
4 	910
5 	905
6 	894
7 	883
8 	871
9 	867
10 	855
11 	857
12 	850
13 	840
14 	836
15 	828
16 	813
17 	808
18 	801
18 	794
19 	793
20 	790
21 	781
22 	786
23 	789
24 	788
25 	786
26 	784
27 	786
28 	783
29 	785
30 	784
31 	785
32 	785
33 	786
34 	786
35 	790
36 	790
37 	794
38 	719
39 	797
40 	797
41 	800
42 	801
43 	806
44 	807
45 	810
46 	806
47 	816
48 	820
49 	821
50 	823
51 	826
52 	829
53 	830
53 	835
54 	826
55 	838
56 	842
57 	841
58 	846
59 	848
60 	851
61 	855
62 	859
63 	862
64 	863
65 	867
66 	868
67 	871
68 	875
69 	874
70 	879
71 	883
72 	884
73 	882
74 	888
75 	893
76 	890
77 	899
78 	898
79 	901
80 	902
81 	901
82 	906
83 	907
84 	907
85 	904
86 	909
87 	910
88 	904
89 	906
89 	902
90 	900
91 	895
92 	797
93 	785
94 	764
96 	734
97 	642
98 	609
99 	589
100 	478

	>;
    };

&bat_comm{
	/* cust_charging.h */
	/* stop charging while in talking mode */
	stop_charging_in_takling = <1 >;
	talking_recharge_voltage = <3800 >;
	talking_sync_time = <60 >;

	/* Battery Temperature Protection */
	mtk_temperature_recharge_support = <1 >;
	max_charge_temperature = <58 >;
	max_charge_temperature_minus_x_degree = <47 >;
	min_charge_temperature = <205 >;
	min_charge_temperature_plus_x_degree = <2 >;
	err_charge_temperature = <0xff >;

	/* Linear Charging Threshold */
	v_pre2cc_thres = <3400 >;	/* unit: mV */
	v_cc2topoff_thres = <4050 >;
	recharging_voltage = <4110 >;
	charging_full_current = <150 >;	/* unit: mA */

	/* Charging Current Setting */
	config_usb_if = <0 >;
	usb_charger_current_suspend = <0 >;	/* Unit: 0.01 mA */
	usb_charger_current_unconfigured = <7000 >;	/* Unit: 0.01 mA */
	usb_charger_current_configured = <50000 >;	/* Unit: 0.01 mA */
	usb_charger_current = <50000 >;	/* Unit: 0.01 mA */
	ac_charger_current = <100000 >;	/* Unit: 0.01 mA */
	non_std_ac_charger_current = <50000 >;	/* Unit: 0.01 mA */
	charging_host_charger_current = <65000 >;	/* Unit: 0.01 mA */
	apple_0_5a_charger_current = <50000 >;	/* Unit: 0.01 mA */
	apple_1_0a_charger_current = <65000 >;	/* Unit: 0.01 mA */
	apple_2_1a_charger_current = <80000 >;	/* Unit: 0.01 mA */

	/* charger error check */
	bat_low_temp_protect_enable = <1 >;
	v_charger_enable = <0 >;	/* 1:on , 0:off */
	v_charger_max = <6500 >;	/* unit: mV */
	v_charger_min = <4400 >;

	/*  Tracking TIME */
	onehundred_percent_tracking_time = <10 >;	/* Unit: second */
	npercent_tracking_time = <20 >;	/* Unit: second */
	sync_to_real_tracking_time = <60 >;	/* Unit: second */
	v_0percent_tracking = <3450 >;	/* Unit: mV */

	/* High battery support */
	high_battery_voltage_support = <1>;
};
